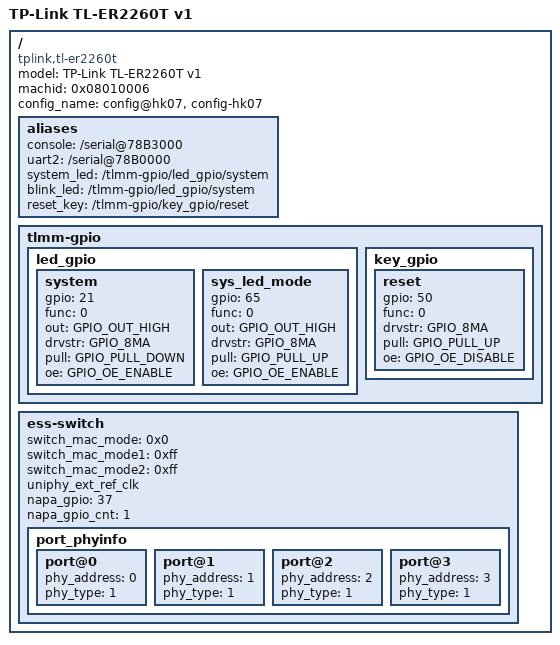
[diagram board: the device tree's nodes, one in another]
// SPDX-License-Identifier: GPL-2.0+

/dts-v1/;
#include "ipq807x-soc.dtsi"
#include <dt-bindings/qcom/gpio-ipq807x.h>

/ {
	model = "TP-Link TL-ER2260T v1";
	compatible = "tplink,tl-er2260t", "qca,ipq807x";
	machid = <0x08010006>;
	config_name = "config@hk07", "config-hk07";

	aliases {
		console = "/serial@78B3000";
		uart2 = "/serial@78B0000";
		system_led = "/tlmm-gpio/led_gpio/system";
		blink_led = "/tlmm-gpio/led_gpio/system";
		reset_key = "/tlmm-gpio/key_gpio/reset";
	};

	tlmm-gpio {
		led_gpio {
			system {
				gpio = <21>;
				func = <0>;
				out = <GPIO_OUT_HIGH>;
				drvstr = <GPIO_8MA>;
				pull = <GPIO_PULL_DOWN>;
				oe = <GPIO_OE_ENABLE>;
			};
			/* GPIO65 high releases the hardware SYS fast-blink override. */
			sys_led_mode {
				gpio = <65>;
				func = <0>;
				out = <GPIO_OUT_HIGH>;
				drvstr = <GPIO_8MA>;
				pull = <GPIO_PULL_UP>;
				oe = <GPIO_OE_ENABLE>;
			};
		};
		key_gpio {
			reset {
				gpio = <50>;
				func = <0>;
				drvstr = <GPIO_8MA>;
				pull = <GPIO_PULL_UP>;
				oe = <GPIO_OE_DISABLE>;
			};
		};
	};

	ess-switch {
		switch_mac_mode = <0x0>;
		switch_mac_mode1 = <0xff>;
		switch_mac_mode2 = <0xff>;
		/* The board supplies a 50 MHz reference, also used by stock Linux. */
		uniphy_ext_ref_clk;
		napa_gpio = <37>;
		napa_gpio_cnt = <1>;
		port_phyinfo {
			port@0 {
				phy_address = <0>;
				phy_type = <1>;
			};
			port@1 {
				phy_address = <1>;
				phy_type = <1>;
			};
			port@2 {
				phy_address = <2>;
				phy_type = <1>;
			};
			port@3 {
				phy_address = <3>;
				phy_type = <1>;
			};
		};
	};
};
